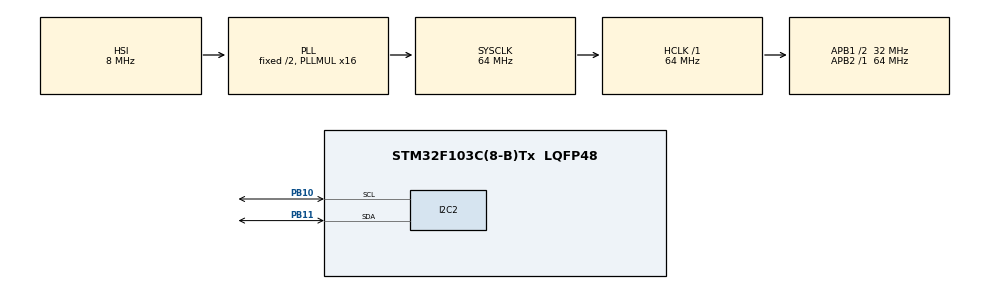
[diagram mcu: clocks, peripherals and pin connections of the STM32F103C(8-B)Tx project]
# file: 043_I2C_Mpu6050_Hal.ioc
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I2C2.I2C_Mode=I2C_Fast
Mcu.Family=STM32F1
Mcu.Name=STM32F103C(8-B)Tx
Mcu.Package=LQFP48
NVIC.PriorityGroup=NVIC_PRIORITYGROUP_4
PA13.Mode=Serial_Wire
PA13.Signal=SYS_JTMS-SWDIO
PA14.Mode=Serial_Wire
PA14.Signal=SYS_JTCK-SWCLK
PB10.Mode=I2C
PB10.Signal=I2C2_SCL
PB11.Mode=I2C
PB11.Signal=I2C2_SDA
ProjectManager.HeapSize=0x200
ProjectManager.StackSize=0x400
ProjectManager.TargetToolchain=STM32CubeIDE
RCC.AHBFreq_Value=64000000
RCC.APB1CLKDivider=RCC_HCLK_DIV2
RCC.APB1Freq_Value=32000000
RCC.APB1TimFreq_Value=64000000
RCC.APB2Freq_Value=64000000
RCC.APB2TimFreq_Value=64000000
RCC.HCLKFreq_Value=64000000
RCC.PLLMUL=RCC_PLL_MUL16
RCC.SYSCLKFreq_VALUE=64000000
RCC.SYSCLKSource=RCC_SYSCLKSOURCE_PLLCLK
RCC.USBFreq_Value=64000000
board=custom

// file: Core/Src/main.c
/* USER CODE BEGIN Header */
/**
  ******************************************************************************
  * @file           : main.c
  * @brief          : Main program body
  ******************************************************************************
  * @attention
  *
  * Copyright (c) 2024 STMicroelectronics.
  * All rights reserved.
  *
  * This software is licensed under terms that can be found in the LICENSE file
  * in the root directory of this software component.
  * If no LICENSE file comes with this software, it is provided AS-IS.
  *
  ******************************************************************************
  */
/* USER CODE END Header */
#include "main.h"

/* USER CODE BEGIN PD */
#define MPU6050_SLAVE_ADDRESS 0x68

/* USER CODE END PD */

I2C_HandleTypeDef hi2c2;

/* USER CODE BEGIN PV */
uint16_t Buffer[6];
uint8_t x, y, z;
uint16_t i = 0;

/* USER CODE END PV */

void SystemClock_Config(void);
static void MX_GPIO_Init(void);
static void MX_I2C2_Init(void);
/* USER CODE BEGIN PFP */
void Scan_Slave_Address(void);
void Mpu6050_Init(void);
void Mpu6050_Read(uint8_t rRegister, uint8_t sizeofdata);
void Mpu6050_Write(uint8_t wRegister, uint8_t wData);

/* USER CODE END PFP */

int main(void)
{

  /* MCU Configuration--------------------------------------------------------*/

  /* Reset of all peripherals, Initializes the Flash interface and the Systick. */
  HAL_Init();

  /* Configure the system clock */
  SystemClock_Config();

  /* Initialize all configured peripherals */
  MX_GPIO_Init();
  MX_I2C2_Init();
  /* USER CODE BEGIN 2 */

  Mpu6050_Init();
  Scan_Slave_Address();

  /* USER CODE END 2 */

  /* Infinite loop */
  while (1)
  {

  }
}

void SystemClock_Config(void)
{
  RCC_OscInitTypeDef RCC_OscInitStruct = {0};
  RCC_ClkInitTypeDef RCC_ClkInitStruct = {0};

  /** Initializes the RCC Oscillators according to the specified parameters
  * in the RCC_OscInitTypeDef structure.
  */
  RCC_OscInitStruct.OscillatorType = RCC_OSCILLATORTYPE_HSI;
  RCC_OscInitStruct.HSIState = RCC_HSI_ON;
  RCC_OscInitStruct.HSICalibrationValue = RCC_HSICALIBRATION_DEFAULT;
  RCC_OscInitStruct.PLL.PLLState = RCC_PLL_ON;
  RCC_OscInitStruct.PLL.PLLSource = RCC_PLLSOURCE_HSI_DIV2;
  RCC_OscInitStruct.PLL.PLLMUL = RCC_PLL_MUL16;
  if (HAL_RCC_OscConfig(&RCC_OscInitStruct) != HAL_OK)
  {
    Error_Handler();
  }

  /** Initializes the CPU, AHB and APB buses clocks
  */
  RCC_ClkInitStruct.ClockType = RCC_CLOCKTYPE_HCLK|RCC_CLOCKTYPE_SYSCLK
                              |RCC_CLOCKTYPE_PCLK1|RCC_CLOCKTYPE_PCLK2;
  RCC_ClkInitStruct.SYSCLKSource = RCC_SYSCLKSOURCE_PLLCLK;
  RCC_ClkInitStruct.AHBCLKDivider = RCC_SYSCLK_DIV1;
  RCC_ClkInitStruct.APB1CLKDivider = RCC_HCLK_DIV2;
  RCC_ClkInitStruct.APB2CLKDivider = RCC_HCLK_DIV1;

  if (HAL_RCC_ClockConfig(&RCC_ClkInitStruct, FLASH_LATENCY_2) != HAL_OK)
  {
    Error_Handler();
  }
}

static void MX_I2C2_Init(void)
{

  hi2c2.Instance = I2C2;
  hi2c2.Init.ClockSpeed = 400000;
  hi2c2.Init.DutyCycle = I2C_DUTYCYCLE_2;
  hi2c2.Init.OwnAddress1 = 0;
  hi2c2.Init.AddressingMode = I2C_ADDRESSINGMODE_7BIT;
  hi2c2.Init.DualAddressMode = I2C_DUALADDRESS_DISABLE;
  hi2c2.Init.OwnAddress2 = 0;
  hi2c2.Init.GeneralCallMode = I2C_GENERALCALL_DISABLE;
  hi2c2.Init.NoStretchMode = I2C_NOSTRETCH_DISABLE;
  if (HAL_I2C_Init(&hi2c2) != HAL_OK)
  {
    Error_Handler();
  }

}

static void MX_GPIO_Init(void)
{

  /* GPIO Ports Clock Enable */
  __HAL_RCC_GPIOB_CLK_ENABLE();
  __HAL_RCC_GPIOA_CLK_ENABLE();

}

/* USER CODE BEGIN 4 */

/*
 * @brief Scan slave address of connected devices to the master and find slave address
 * @param None
 * retval None
 */
void Scan_Slave_Address(void){

	for(i=0; i <= 255 ; i++){
		if(HAL_I2C_IsDeviceReady(&hi2c2, i, 1, 100) == HAL_OK)
			break;
	}
}

/*
 * @brief Mpu6050 sensor Initialization Function
 * @param None
 * @retval None
 */
void Mpu6050_Init(void){

	Mpu6050_Read(117, 1); 													// Read whoamI register

	Mpu6050_Write(0x6b, 0x8);												// power management: reset all register of sensor
	HAL_Delay(100);
	Mpu6050_Write(0x6b, 0x18); 												// power management: temprature disabled, sleep disabled, clock 8 mhz

	Mpu6050_Read(0x6b, 2);
}

/*
 * @brief Mpu6050 sensor Read function: Read from memory of the sensor
 * @param uint8_t rRegister: register to be read,
 * 		  uint8_t sizeofdata: number of byte of register to be read
 * @retval uint8_t
 */

void Mpu6050_Read(uint8_t rRegister, uint8_t sizeofdata){

	HAL_I2C_Mem_Read(&hi2c2, MPU6050_SLAVE_ADDRESS, rRegister, 1, Buffer, sizeofdata, 100);

}

/*
 * @brief Mpu6050 sensor Write function: Write data which we declare to the register to be written on the sensor
 * @param uint8_t wRegister: Register of the sensor wanted to be changed
 * 		  uimt8_t sizeofdata: number of byte of data wanted to write
 * @retval None
 */
void Mpu6050_Write(uint8_t wRegister, uint8_t wData){

	uint8_t data[2] = {0};
	data[0] = wRegister;
	data[1] = wData;

	HAL_I2C_Master_Transmit(&hi2c2, MPU6050_SLAVE_ADDRESS, data, 2, 100);

}

/* USER CODE END 4 */

void Error_Handler(void)
{
  __disable_irq();
  while (1)
  {
  }
}
